AUTOSAR XML (schema 00044)
package /E40_Platform_System_SystemPackage/Components
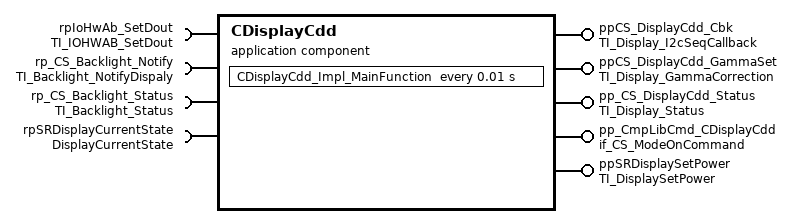
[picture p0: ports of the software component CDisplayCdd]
  application sw component type CDisplayCdd
    4 x provide port:
      ppCS_DisplayCdd_Cbk: server-com-spec{operation=I2cSeqEndCallback, queue-length=1}, provided-interface=TI_Display_I2cSeqCallback
      ppCS_DisplayCdd_GammaSet: provided-com-specs=[{operation=GetGammaCorrectionStatus, queue-length=1}, {operation=SetGammaCorrection, queue-length=1}], provided-interface=TI_Display_GammaCorrection
      pp_CS_DisplayCdd_Status: provided-com-specs=[{operation=GetStatus, queue-length=1}, {operation=SetState, queue-length=1}], provided-interface=TI_Display_Status
      pp_CmpLibCmd_CDisplayCdd: server-com-spec{operation=Impl_OnCommand, queue-length=1}, provided-interface=if_CS_ModeOnCommand
    require port rpIoHwAb_SetDout: required-com-specs=[SetOutputGroup, SetOutputPin], required-interface=TI_IOHWAB_SetDout
    require port rp_CS_Backlight_Notify: client-com-spec=NotifyDisplayPowerState, required-interface=TI_Backlight_NotifyDispaly
    require port rp_CS_Backlight_Status: client-com-spec=GetStatus, required-interface=TI_Backlight_Status
    provide port ppSRDisplaySetPower: nonqueued-sender-com-spec{data-element=DisplaySetPowerData, init-value=constant-reference=CDisplayCddDisplaySetPowerDataValue0}, provided-interface=TI_DisplaySetPower
    require port rpSRDisplayCurrentState: nonqueued-receiver-com-spec{data-element=DisplayCurrentStateData, init-value=constant-reference=CDisplayCddDisplayCurrentStateDataValue0}, required-interface=DisplayCurrentState
    behavior IB_CDisplayCdd
      operation invoked event OIE_ppCS_DisplayCdd_GammaSet_CDisplayCdd_GetGammaCorrectionStatusTrigByGetGammaCorrectionStatus: start-on-event=CDisplayCdd_GetGammaCorrectionStatus, operation=ppCS_DisplayCdd_GammaSet.GetGammaCorrectionStatus
      operation invoked event OIE_pp_CS_DisplayCdd_Status_CDisplayCdd_GetStatusTrigByGetStatus: start-on-event=CDisplayCdd_GetStatus, operation=pp_CS_DisplayCdd_Status.GetStatus
      operation invoked event OIE_ppCS_DisplayCdd_Cbk_CDisplayCdd_I2cSeqEndCallbackTrigByI2cSeqEndCallback: start-on-event=CDisplayCdd_I2cSeqEndCallback, operation=ppCS_DisplayCdd_Cbk.I2cSeqEndCallback
      timing event TECDisplayCdd_Impl_MainFunction: start-on-event=CDisplayCdd_Impl_MainFunction, period=0.01
      operation invoked event OIE_pp_CmpLibCmd_CDisplayCdd_CDisplayCdd_Impl_OnCommandTrigByImpl_OnCommand: start-on-event=CDisplayCdd_Impl_OnCommand, operation=pp_CmpLibCmd_CDisplayCdd.Impl_OnCommand
      operation invoked event OIE_ppCS_DisplayCdd_GammaSet_CDisplayCdd_SetGammaCorrectionTrigBySetGammaCorrection: start-on-event=CDisplayCdd_SetGammaCorrection, operation=ppCS_DisplayCdd_GammaSet.SetGammaCorrection
      operation invoked event OIE_pp_CS_DisplayCdd_Status_CDisplayCdd_SetStateTrigBySetState: start-on-event=CDisplayCdd_SetState, operation=pp_CS_DisplayCdd_Status.SetState
      port-api-options:
        enable-take-address=false, indirect-api=false, port=ppCS_DisplayCdd_Cbk
        enable-take-address=false, indirect-api=false, port=ppCS_DisplayCdd_GammaSet
        enable-take-address=false, indirect-api=false, port=pp_CS_DisplayCdd_Status
        enable-take-address=false, indirect-api=false, port=pp_CmpLibCmd_CDisplayCdd
        enable-take-address=false, indirect-api=false, port=rpIoHwAb_SetDout
        enable-take-address=false, indirect-api=false, port=rp_CS_Backlight_Notify
        enable-take-address=false, indirect-api=false, port=rp_CS_Backlight_Status
        enable-take-address=false, indirect-api=false, port=ppSRDisplaySetPower
        enable-take-address=false, indirect-api=false, port=rpSRDisplayCurrentState
      7 x runnable, all with can-be-invoked-concurrently=true:
        CDisplayCdd_GetGammaCorrectionStatus
        CDisplayCdd_GetStatus
          data-receive-point-by-arguments:
            access DRA_rpSRDisplayCurrentState_DisplayCurrentStateData: accessed-variable=rpSRDisplayCurrentState.DisplayCurrentStateData
          data-send-points:
            access DWA_ppSRDisplaySetPower_DisplaySetPowerData: accessed-variable=ppSRDisplaySetPower.DisplaySetPowerData
          4 x sync call:
            OA_rpIoHwAb_SetDout_SetOutputGroup: operation=rpIoHwAb_SetDout.SetOutputGroup
            OA_rpIoHwAb_SetDout_SetOutputPin: operation=rpIoHwAb_SetDout.SetOutputPin
            OA_rp_CS_Backlight_Notify_NotifyDisplayPowerState: operation=rp_CS_Backlight_Notify.NotifyDisplayPowerState
            OA_rp_CS_Backlight_Status_GetStatus: operation=rp_CS_Backlight_Status.GetStatus
        CDisplayCdd_I2cSeqEndCallback
        CDisplayCdd_Impl_MainFunction
          data-receive-point-by-arguments:
            access DRA_rpSRDisplayCurrentState_DisplayCurrentStateData: accessed-variable=rpSRDisplayCurrentState.DisplayCurrentStateData
          data-send-points:
            access DWA_ppSRDisplaySetPower_DisplaySetPowerData: accessed-variable=ppSRDisplaySetPower.DisplaySetPowerData
          4 x sync call:
            OA_rpIoHwAb_SetDout_SetOutputGroup: operation=rpIoHwAb_SetDout.SetOutputGroup
            OA_rpIoHwAb_SetDout_SetOutputPin: operation=rpIoHwAb_SetDout.SetOutputPin
            OA_rp_CS_Backlight_Notify_NotifyDisplayPowerState: operation=rp_CS_Backlight_Notify.NotifyDisplayPowerState
            OA_rp_CS_Backlight_Status_GetStatus: operation=rp_CS_Backlight_Status.GetStatus
        CDisplayCdd_Impl_OnCommand
          data-receive-point-by-arguments:
            access DRA_rpSRDisplayCurrentState_DisplayCurrentStateData: accessed-variable=rpSRDisplayCurrentState.DisplayCurrentStateData
          data-send-points:
            access DWA_ppSRDisplaySetPower_DisplaySetPowerData: accessed-variable=ppSRDisplaySetPower.DisplaySetPowerData
          4 x sync call:
            OA_rpIoHwAb_SetDout_SetOutputGroup: operation=rpIoHwAb_SetDout.SetOutputGroup
            OA_rpIoHwAb_SetDout_SetOutputPin: operation=rpIoHwAb_SetDout.SetOutputPin
            OA_rp_CS_Backlight_Notify_NotifyDisplayPowerState: operation=rp_CS_Backlight_Notify.NotifyDisplayPowerState
            OA_rp_CS_Backlight_Status_GetStatus: operation=rp_CS_Backlight_Status.GetStatus
        CDisplayCdd_SetGammaCorrection
        CDisplayCdd_SetState
          data-receive-point-by-arguments:
            access DRA_rpSRDisplayCurrentState_DisplayCurrentStateData: accessed-variable=rpSRDisplayCurrentState.DisplayCurrentStateData
          data-send-points:
            access DWA_ppSRDisplaySetPower_DisplaySetPowerData: accessed-variable=ppSRDisplaySetPower.DisplaySetPowerData
          4 x sync call:
            OA_rpIoHwAb_SetDout_SetOutputGroup: operation=rpIoHwAb_SetDout.SetOutputGroup
            OA_rpIoHwAb_SetDout_SetOutputPin: operation=rpIoHwAb_SetDout.SetOutputPin
            OA_rp_CS_Backlight_Notify_NotifyDisplayPowerState: operation=rp_CS_Backlight_Notify.NotifyDisplayPowerState
            OA_rp_CS_Backlight_Status_GetStatus: operation=rp_CS_Backlight_Status.GetStatus
  swc implementation IMPL_CDisplayCdd: behavior=IB_CDisplayCdd
